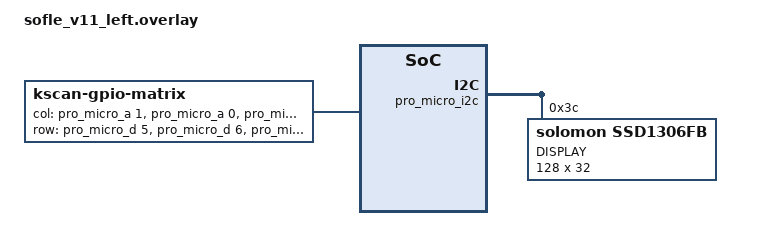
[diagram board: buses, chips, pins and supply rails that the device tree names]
#include "sofle_v11.dtsi"

&default_transform {
	col-offset = <1>;
};

/ {
	kscan0: kscan {
		compatible = "zmk,kscan-gpio-matrix";
		label = "KSCAN";
		diode-direction = "col2row";

		col-gpios
		= <&pro_micro_a  1 GPIO_ACTIVE_HIGH>
		, <&pro_micro_a  0 GPIO_ACTIVE_HIGH>
		, <&pro_micro_d 15 GPIO_ACTIVE_HIGH>
		, <&pro_micro_d 14 GPIO_ACTIVE_HIGH>
		, <&pro_micro_d 16 GPIO_ACTIVE_HIGH>
		, <&pro_micro_d 10 GPIO_ACTIVE_HIGH>
		;
		row-gpios
            = <&pro_micro_d 5 (GPIO_ACTIVE_HIGH | GPIO_PULL_DOWN)>
            , <&pro_micro_d 6 (GPIO_ACTIVE_HIGH | GPIO_PULL_DOWN)>
            , <&pro_micro_d 7 (GPIO_ACTIVE_HIGH | GPIO_PULL_DOWN)>
            , <&pro_micro_d 8 (GPIO_ACTIVE_HIGH | GPIO_PULL_DOWN)>
            , <&pro_micro_d 9 (GPIO_ACTIVE_HIGH | GPIO_PULL_DOWN)>
            ;
	};
};

&pro_micro_i2c {
    status = "okay";

    ssd1306@3c {
        compatible = "solomon,ssd1306fb";
        reg = <0x3c>;
        label = "DISPLAY";
        width = <128>;
        height = <32>;
        segment-offset = <0>;
        page-offset = <0>;
        display-offset = <0>;
        multiplex-ratio = <31>;
        segment-remap;
        com-invdir;
        com-sequential;
        prechargep = <0x22>;
    };
};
